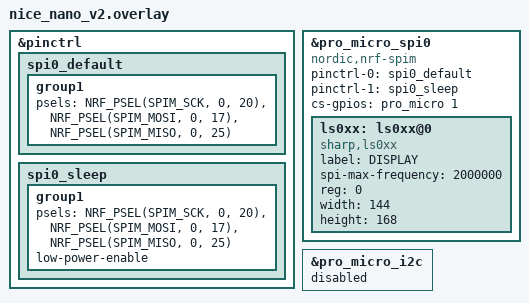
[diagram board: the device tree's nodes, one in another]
// note this file was copied in from the lily58 folder within the main zmk repository,
// credit should be given to the creator 'The ZMK Contributors'.
#include <dt-bindings/led/led.h>

/*
 * Copyright (c) 2022 The ZMK Contributors
 *
 * SPDX-License-Identifier: MIT
 */

;&pinctrl {
    spi0_default: spi0_default {
        group1 {
            psels = <NRF_PSEL(SPIM_SCK, 0, 20)>,
                <NRF_PSEL(SPIM_MOSI, 0, 17)>,
                <NRF_PSEL(SPIM_MISO, 0, 25)>;
        };
    };
    spi0_sleep: spi0_sleep {
        group1 {
            psels = <NRF_PSEL(SPIM_SCK, 0, 20)>,
                <NRF_PSEL(SPIM_MOSI, 0, 17)>,
                <NRF_PSEL(SPIM_MISO, 0, 25)>;
            low-power-enable;
        };
    };
};

&pro_micro_spi0 {
    compatible = "nordic,nrf-spim";
    status = "okay";

    pinctrl-0 = <&spi0_default>;
    pinctrl-1 = <&spi0_sleep>;
    pinctrl-names = "default", "sleep";

    cs-gpios = <&pro_micro 1 GPIO_ACTIVE_HIGH>;

    ls0xx:  ls0xx@0 {
        compatible = "sharp,ls0xx";
        label = "DISPLAY";
        spi-max-frequency = <2000000>;
        reg = <0>;
        width = <144>;
        height = <168>;
    };
};

&pro_micro_i2c {
    status = "disabled";
};
